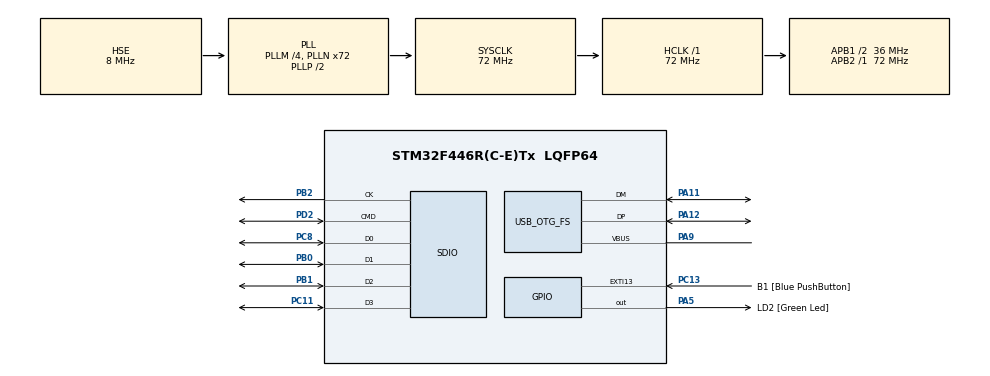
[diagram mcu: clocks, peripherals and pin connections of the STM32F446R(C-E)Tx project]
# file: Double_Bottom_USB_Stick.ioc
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Dma.Request0=SDIO_RX
Dma.Request1=SDIO_TX
Dma.SDIO_RX.0.Direction=DMA_PERIPH_TO_MEMORY
Dma.SDIO_RX.0.FIFOMode=DMA_FIFOMODE_ENABLE
Dma.SDIO_RX.0.FIFOThreshold=DMA_FIFO_THRESHOLD_FULL
Dma.SDIO_RX.0.Instance=DMA2_Stream3
Dma.SDIO_RX.0.MemBurst=DMA_MBURST_INC4
Dma.SDIO_RX.0.MemDataAlignment=DMA_MDATAALIGN_WORD
Dma.SDIO_RX.0.MemInc=DMA_MINC_ENABLE
Dma.SDIO_RX.0.Mode=DMA_PFCTRL
Dma.SDIO_RX.0.PeriphBurst=DMA_PBURST_INC4
Dma.SDIO_RX.0.PeriphDataAlignment=DMA_PDATAALIGN_WORD
Dma.SDIO_RX.0.PeriphInc=DMA_PINC_DISABLE
Dma.SDIO_RX.0.Priority=DMA_PRIORITY_VERY_HIGH
Dma.SDIO_TX.1.Direction=DMA_MEMORY_TO_PERIPH
Dma.SDIO_TX.1.FIFOMode=DMA_FIFOMODE_ENABLE
Dma.SDIO_TX.1.FIFOThreshold=DMA_FIFO_THRESHOLD_FULL
Dma.SDIO_TX.1.Instance=DMA2_Stream6
Dma.SDIO_TX.1.MemBurst=DMA_MBURST_INC4
Dma.SDIO_TX.1.MemDataAlignment=DMA_MDATAALIGN_WORD
Dma.SDIO_TX.1.MemInc=DMA_MINC_ENABLE
Dma.SDIO_TX.1.Mode=DMA_PFCTRL
Dma.SDIO_TX.1.PeriphBurst=DMA_PBURST_INC4
Dma.SDIO_TX.1.PeriphDataAlignment=DMA_PDATAALIGN_WORD
Dma.SDIO_TX.1.PeriphInc=DMA_PINC_DISABLE
Dma.SDIO_TX.1.Priority=DMA_PRIORITY_VERY_HIGH
FATFS._CODE_PAGE=437
FATFS._FS_LOCK=1
FATFS._FS_MINIMIZE=0
FATFS._MAX_SS=4096
FATFS._USE_FASTSEEK=0
FATFS._USE_MKFS=0
Mcu.Family=STM32F4
Mcu.Name=STM32F446R(C-E)Tx
Mcu.Package=LQFP64
NVIC.DMA2_Stream3_IRQn=true\:3\:0\:true\:false\:true
NVIC.DMA2_Stream6_IRQn=true\:3\:0\:true\:false\:true
NVIC.OTG_FS_IRQn=true\:4\:0\:true\:false\:true
NVIC.PriorityGroup=NVIC_PRIORITYGROUP_4
NVIC.SDIO_IRQn=true\:2\:0\:true\:false\:true
NVIC.TIM8_TRG_COM_TIM14_IRQn=true\:15\:0\:true\:false\:true
PA11.Mode=Device_Only
PA11.Signal=USB_OTG_FS_DM
PA12.Mode=Device_Only
PA12.Signal=USB_OTG_FS_DP
PA13.GPIO_Label=TMS
PA13.Mode=Serial_Wire
PA13.Signal=SYS_JTMS-SWDIO
PA14.GPIO_Label=TCK
PA14.Mode=Serial_Wire
PA14.Signal=SYS_JTCK-SWCLK
PA2.GPIO_Label=USART_TX
PA2.Signal=USART2_TX
PA3.GPIO_Label=USART_RX
PA3.Signal=USART2_RX
PA5.GPIO_Label=LD2 [Green Led]
PA5.Signal=GPIO_Output
PA9.Mode=Activate_VBUS
PA9.Signal=USB_OTG_FS_VBUS
PB0.Mode=SD_4_bits_Wide_bus
PB0.Signal=SDIO_D1
PB1.Mode=SD_4_bits_Wide_bus
PB1.Signal=SDIO_D2
PB2.Mode=SD_4_bits_Wide_bus
PB2.Signal=SDIO_CK
PB3.GPIO_Label=SWO
PB3.Signal=SYS_JTDO-SWO
PC11.Mode=SD_4_bits_Wide_bus
PC11.Signal=SDIO_D3
PC13.GPIO_Label=B1 [Blue PushButton]
PC13.GPIO_ModeDefaultEXTI=GPIO_MODE_EVT_RISING
PC13.Signal=GPXTI13
PC14-OSC32_IN.Signal=RCC_OSC32_IN
PC15-OSC32_OUT.Signal=RCC_OSC32_OUT
PC8.Mode=SD_4_bits_Wide_bus
PC8.Signal=SDIO_D0
PD2.Mode=SD_4_bits_Wide_bus
PD2.Signal=SDIO_CMD
PH0-OSC_IN.Mode=HSE-External-Oscillator
PH0-OSC_IN.Signal=RCC_OSC_IN
PH1-OSC_OUT.Mode=HSE-External-Oscillator
PH1-OSC_OUT.Signal=RCC_OSC_OUT
ProjectManager.HeapSize=0x600
ProjectManager.StackSize=0x2400
ProjectManager.TargetToolchain=TrueSTUDIO
RCC.AHBFreq_Value=72000000
RCC.APB1CLKDivider=RCC_HCLK_DIV2
RCC.APB1Freq_Value=36000000
RCC.APB1TimFreq_Value=72000000
RCC.APB2Freq_Value=72000000
RCC.APB2TimFreq_Value=72000000
RCC.CortexFreq_Value=72000000
RCC.FLatency-AdvancedSettings=FLASH_LATENCY_2
RCC.HCLKFreq_Value=72000000
RCC.HSE_VALUE=8000000
RCC.HSI_VALUE=16000000
RCC.LSE_VALUE=32768
RCC.PLLM=4
RCC.PLLN=72
RCC.PLLQ=3
RCC.SYSCLKFreq_VALUE=72000000
RCC.SYSCLKSource=RCC_SYSCLKSOURCE_PLLCLK
RCC.USBFreq_Value=48000000
RCC.VCOOutputFreq_Value=144000000
SDIO.BusWide=SDIO_BUS_WIDE_1B
SDIO.WideMode=SDIO_BUS_WIDE_4B
TIM14.Period=2000
TIM14.Prescaler=35999
USB_DEVICE.CLASS_NAME-MSC_FS=MSC
USB_DEVICE.USBD_HandleTypeDef-MSC_FS=hUsbDeviceFS
USB_DEVICE.VirtualMode-MSC_FS=Msc
USB_DEVICE.VirtualModeFS=Msc_FS
USB_OTG_FS.VirtualMode=Device_Only
VP_FATFS_VS_SDIO.Mode=SDIO
VP_TIM14_VS_ClockSourceINT.Mode=Enable_Timer
VP_USB_DEVICE_VS_USB_DEVICE_MSC_FS.Mode=MSC_FS
board=NUCLEO-F446RE

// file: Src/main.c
/**
  ******************************************************************************
  * File Name          : main.c
  * Description        : Main program body
  ******************************************************************************
  *
  * Copyright (c) 2017 STMicroelectronics International N.V.
  * All rights reserved.
  *
  * Redistribution and use in source and binary forms, with or without
  * modification, are permitted, provided that the following conditions are met:
  *
  * 1. Redistribution of source code must retain the above copyright notice,
  *    this list of conditions and the following disclaimer.
  * 2. Redistributions in binary form must reproduce the above copyright notice,
  *    this list of conditions and the following disclaimer in the documentation
  *    and/or other materials provided with the distribution.
  * 3. Neither the name of STMicroelectronics nor the names of other
  *    contributors to this software may be used to endorse or promote products
  *    derived from this software without specific written permission.
  * 4. This software, including modifications and/or derivative works of this
  *    software, must execute solely and exclusively on microcontroller or
  *    microprocessor devices manufactured by or for STMicroelectronics.
  * 5. Redistribution and use of this software other than as permitted under
  *    this license is void and will automatically terminate your rights under
  *    this license.
  *
  * THIS SOFTWARE IS PROVIDED BY STMICROELECTRONICS AND CONTRIBUTORS "AS IS"
  * AND ANY EXPRESS, IMPLIED OR STATUTORY WARRANTIES, INCLUDING, BUT NOT
  * LIMITED TO, THE IMPLIED WARRANTIES OF MERCHANTABILITY, FITNESS FOR A
  * PARTICULAR PURPOSE AND NON-INFRINGEMENT OF THIRD PARTY INTELLECTUAL PROPERTY
  * RIGHTS ARE DISCLAIMED TO THE FULLEST EXTENT PERMITTED BY LAW. IN NO EVENT
  * SHALL STMICROELECTRONICS OR CONTRIBUTORS BE LIABLE FOR ANY DIRECT, INDIRECT,
  * INCIDENTAL, SPECIAL, EXEMPLARY, OR CONSEQUENTIAL DAMAGES (INCLUDING, BUT NOT
  * LIMITED TO, PROCUREMENT OF SUBSTITUTE GOODS OR SERVICES; LOSS OF USE, DATA,
  * OR PROFITS; OR BUSINESS INTERRUPTION) HOWEVER CAUSED AND ON ANY THEORY OF
  * LIABILITY, WHETHER IN CONTRACT, STRICT LIABILITY, OR TORT (INCLUDING
  * NEGLIGENCE OR OTHERWISE) ARISING IN ANY WAY OUT OF THE USE OF THIS SOFTWARE,
  * EVEN IF ADVISED OF THE POSSIBILITY OF SUCH DAMAGE.
  *
  ******************************************************************************
  */
#include "main.h"
#include "stm32f4xx_hal.h"
#include "fatfs.h"
#include "usb_device.h"

/* USER CODE BEGIN Includes */
#include "user_interface.h"
/* USER CODE END Includes */

SD_HandleTypeDef hsd;
HAL_SD_CardInfoTypedef SDCardInfo;
DMA_HandleTypeDef hdma_sdio_rx;
DMA_HandleTypeDef hdma_sdio_tx;

TIM_HandleTypeDef htim14;

/* USER CODE BEGIN PV */
/* Private variables ---------------------------------------------------------*/

/* USER CODE END PV */

void SystemClock_Config(void);
void Error_Handler(void);
static void MX_GPIO_Init(void);
static void MX_DMA_Init(void);
static void MX_SDIO_SD_Init(void);
static void MX_TIM14_Init(void);

/* USER CODE BEGIN PFP */
/* Private function prototypes -----------------------------------------------*/

/* USER CODE END PFP */

int main(void)
{

  /* MCU Configuration----------------------------------------------------------*/

  /* Reset of all peripherals, Initializes the Flash interface and the Systick. */
  HAL_Init();

  /* Configure the system clock */
  SystemClock_Config();

  /* Initialize all configured peripherals */
  MX_GPIO_Init();
  MX_DMA_Init();
  MX_SDIO_SD_Init();
  MX_FATFS_Init();
  MX_TIM14_Init();

  /* USER CODE BEGIN 2 */
  initSDCard();
  HAL_TIM_Base_Start_IT(&htim14);
  MX_USB_DEVICE_Init();
  /* USER CODE END 2 */

  /* Infinite loop */
  while (1)
  {

  }

}

/** System Clock Configuration
*/
void SystemClock_Config(void)
{

  RCC_OscInitTypeDef RCC_OscInitStruct;
  RCC_ClkInitTypeDef RCC_ClkInitStruct;
  RCC_PeriphCLKInitTypeDef PeriphClkInitStruct;

    /**Configure the main internal regulator output voltage
    */
  __HAL_RCC_PWR_CLK_ENABLE();

  __HAL_PWR_VOLTAGESCALING_CONFIG(PWR_REGULATOR_VOLTAGE_SCALE3);

    /**Initializes the CPU, AHB and APB busses clocks
    */
  RCC_OscInitStruct.OscillatorType = RCC_OSCILLATORTYPE_HSE;
  RCC_OscInitStruct.HSEState = RCC_HSE_ON;
  RCC_OscInitStruct.PLL.PLLState = RCC_PLL_ON;
  RCC_OscInitStruct.PLL.PLLSource = RCC_PLLSOURCE_HSE;
  RCC_OscInitStruct.PLL.PLLM = 4;
  RCC_OscInitStruct.PLL.PLLN = 72;
  RCC_OscInitStruct.PLL.PLLP = RCC_PLLP_DIV2;
  RCC_OscInitStruct.PLL.PLLQ = 3;
  RCC_OscInitStruct.PLL.PLLR = 2;
  if (HAL_RCC_OscConfig(&RCC_OscInitStruct) != HAL_OK)
  {
    Error_Handler();
  }

    /**Initializes the CPU, AHB and APB busses clocks
    */
  RCC_ClkInitStruct.ClockType = RCC_CLOCKTYPE_HCLK|RCC_CLOCKTYPE_SYSCLK
                              |RCC_CLOCKTYPE_PCLK1|RCC_CLOCKTYPE_PCLK2;
  RCC_ClkInitStruct.SYSCLKSource = RCC_SYSCLKSOURCE_PLLCLK;
  RCC_ClkInitStruct.AHBCLKDivider = RCC_SYSCLK_DIV1;
  RCC_ClkInitStruct.APB1CLKDivider = RCC_HCLK_DIV2;
  RCC_ClkInitStruct.APB2CLKDivider = RCC_HCLK_DIV1;

  if (HAL_RCC_ClockConfig(&RCC_ClkInitStruct, FLASH_LATENCY_2) != HAL_OK)
  {
    Error_Handler();
  }

  PeriphClkInitStruct.PeriphClockSelection = RCC_PERIPHCLK_SDIO|RCC_PERIPHCLK_CLK48;
  PeriphClkInitStruct.Clk48ClockSelection = RCC_CLK48CLKSOURCE_PLLQ;
  PeriphClkInitStruct.SdioClockSelection = RCC_SDIOCLKSOURCE_CLK48;
  if (HAL_RCCEx_PeriphCLKConfig(&PeriphClkInitStruct) != HAL_OK)
  {
    Error_Handler();
  }

    /**Configure the Systick interrupt time
    */
  HAL_SYSTICK_Config(HAL_RCC_GetHCLKFreq()/1000);

    /**Configure the Systick
    */
  HAL_SYSTICK_CLKSourceConfig(SYSTICK_CLKSOURCE_HCLK);

  /* SysTick_IRQn interrupt configuration */
  HAL_NVIC_SetPriority(SysTick_IRQn, 0, 0);
}

/* SDIO init function */
static void MX_SDIO_SD_Init(void)
{

  hsd.Instance = SDIO;
  hsd.Init.ClockEdge = SDIO_CLOCK_EDGE_RISING;
  hsd.Init.ClockBypass = SDIO_CLOCK_BYPASS_DISABLE;
  hsd.Init.ClockPowerSave = SDIO_CLOCK_POWER_SAVE_DISABLE;
  hsd.Init.BusWide = SDIO_BUS_WIDE_1B;
  hsd.Init.HardwareFlowControl = SDIO_HARDWARE_FLOW_CONTROL_DISABLE;
  hsd.Init.ClockDiv = 0;

}

/* TIM14 init function */
static void MX_TIM14_Init(void)
{

  htim14.Instance = TIM14;
  htim14.Init.Prescaler = 35999;
  htim14.Init.CounterMode = TIM_COUNTERMODE_UP;
  htim14.Init.Period = 2000;
  htim14.Init.ClockDivision = TIM_CLOCKDIVISION_DIV1;
  if (HAL_TIM_Base_Init(&htim14) != HAL_OK)
  {
    Error_Handler();
  }

}

static void MX_DMA_Init(void)
{
  /* DMA controller clock enable */
  __HAL_RCC_DMA2_CLK_ENABLE();

  /* DMA interrupt init */
  /* DMA2_Stream3_IRQn interrupt configuration */
  HAL_NVIC_SetPriority(DMA2_Stream3_IRQn, 3, 0);
  HAL_NVIC_EnableIRQ(DMA2_Stream3_IRQn);
  /* DMA2_Stream6_IRQn interrupt configuration */
  HAL_NVIC_SetPriority(DMA2_Stream6_IRQn, 3, 0);
  HAL_NVIC_EnableIRQ(DMA2_Stream6_IRQn);

}

/** Configure pins as
        * Analog
        * Input
        * Output
        * EVENT_OUT
        * EXTI
     PA2   ------> USART2_TX
     PA3   ------> USART2_RX
*/
static void MX_GPIO_Init(void)
{

  GPIO_InitTypeDef GPIO_InitStruct;

  /* GPIO Ports Clock Enable */
  __HAL_RCC_GPIOC_CLK_ENABLE();
  __HAL_RCC_GPIOH_CLK_ENABLE();
  __HAL_RCC_GPIOA_CLK_ENABLE();
  __HAL_RCC_GPIOB_CLK_ENABLE();
  __HAL_RCC_GPIOD_CLK_ENABLE();

  /*Configure GPIO pin : B1_Pin */
  GPIO_InitStruct.Pin = B1_Pin;
  GPIO_InitStruct.Mode = GPIO_MODE_EVT_RISING;
  GPIO_InitStruct.Pull = GPIO_NOPULL;
  HAL_GPIO_Init(B1_GPIO_Port, &GPIO_InitStruct);

  /*Configure GPIO pins : USART_TX_Pin USART_RX_Pin */
  GPIO_InitStruct.Pin = USART_TX_Pin|USART_RX_Pin;
  GPIO_InitStruct.Mode = GPIO_MODE_AF_PP;
  GPIO_InitStruct.Pull = GPIO_NOPULL;
  GPIO_InitStruct.Speed = GPIO_SPEED_FREQ_VERY_HIGH;
  GPIO_InitStruct.Alternate = GPIO_AF7_USART2;
  HAL_GPIO_Init(GPIOA, &GPIO_InitStruct);

  /*Configure GPIO pin : LD2_Pin */
  GPIO_InitStruct.Pin = LD2_Pin;
  GPIO_InitStruct.Mode = GPIO_MODE_OUTPUT_PP;
  GPIO_InitStruct.Pull = GPIO_NOPULL;
  GPIO_InitStruct.Speed = GPIO_SPEED_FREQ_LOW;
  HAL_GPIO_Init(LD2_GPIO_Port, &GPIO_InitStruct);

  /*Configure GPIO pin Output Level */
  HAL_GPIO_WritePin(LD2_GPIO_Port, LD2_Pin, GPIO_PIN_RESET);

}

/* USER CODE BEGIN 4 */
void HAL_TIM_PeriodElapsedCallback(TIM_HandleTypeDef *htim)
{
  if (htim->Instance == TIM14)
  {
    checkConfFiles();
  }
}
/* USER CODE END 4 */

void Error_Handler(void)
{
  while(1)
  {
  }
}

/************************ (C) COPYRIGHT STMicroelectronics *****END OF FILE****/
